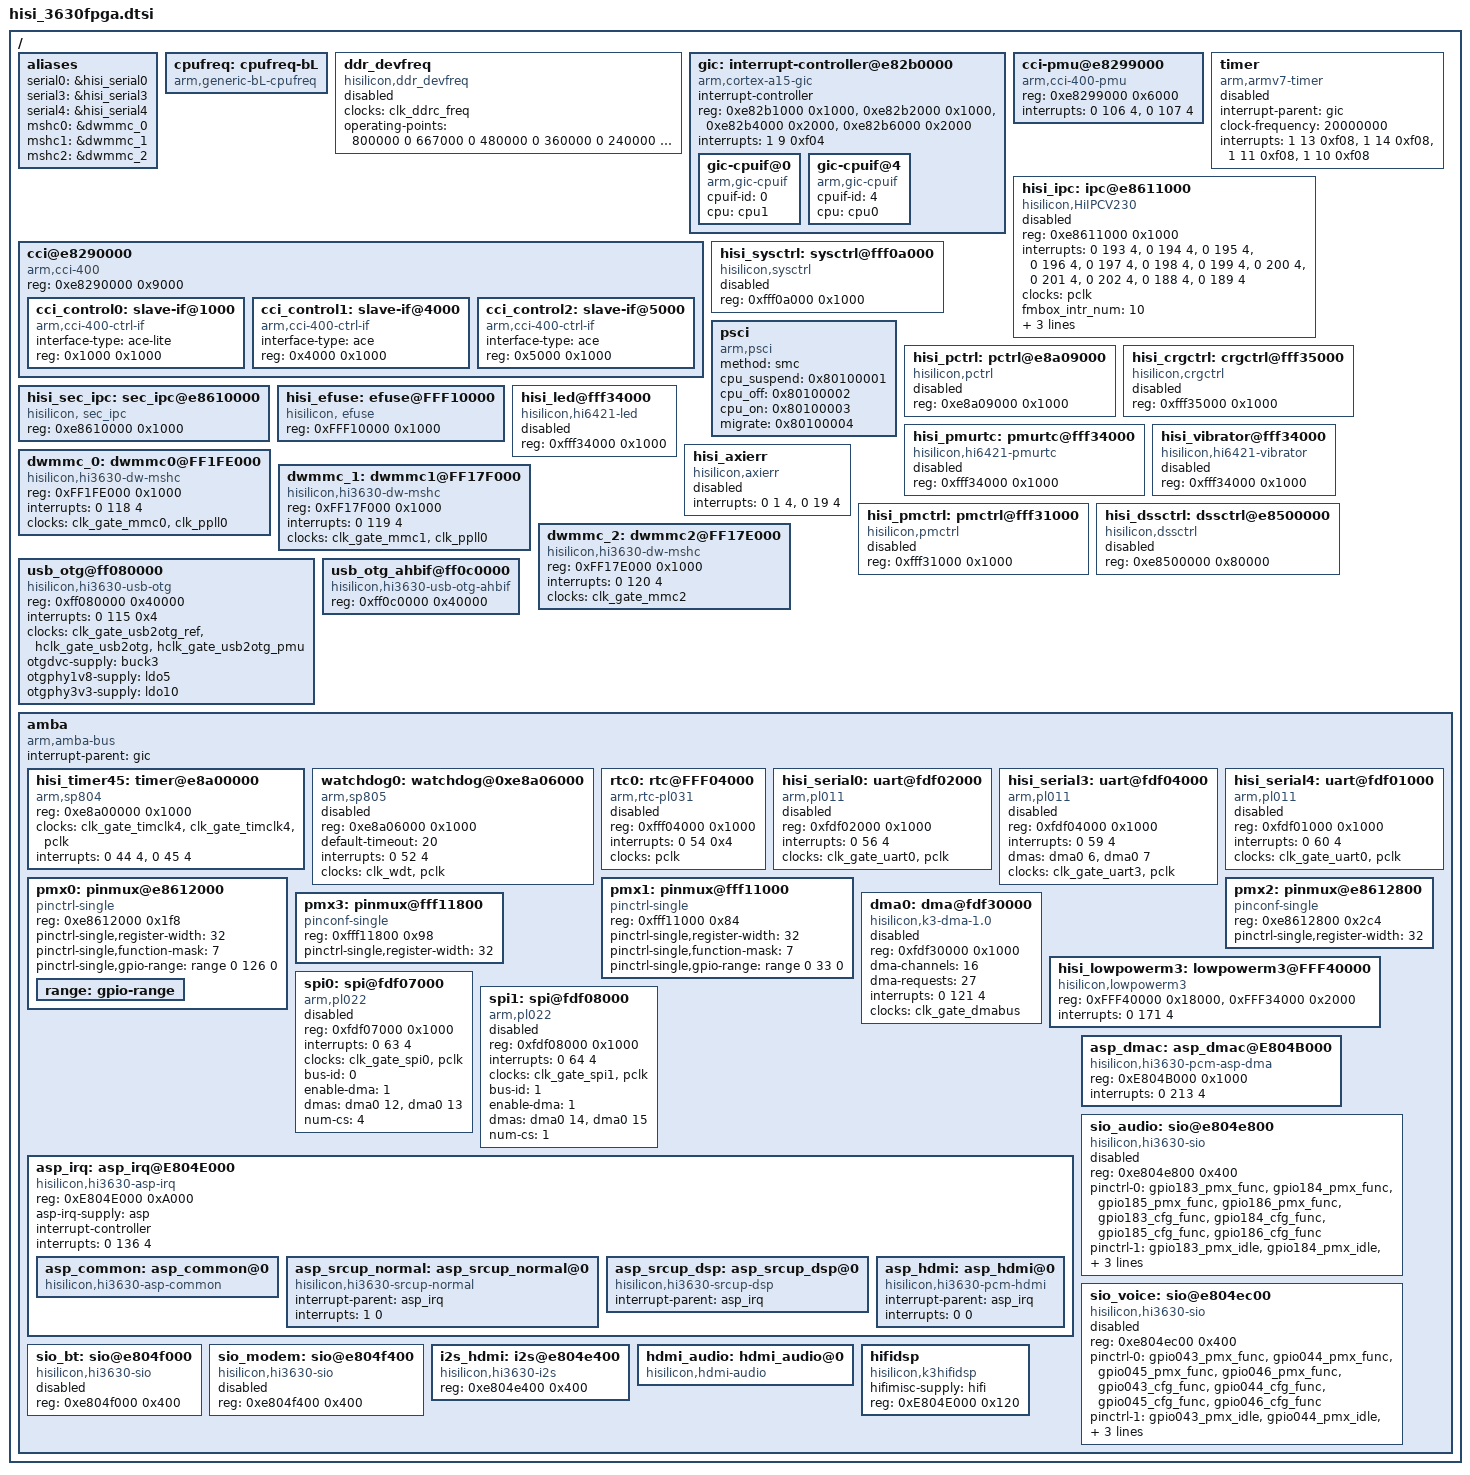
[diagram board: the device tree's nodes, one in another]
/*
 * Hisilicon Ltd. Hi3630FPGA SoC
 *
 * Copyright (C) 2013 Hisilicon Technologies CO., Ltd.
 *
 * This program is free software; you can redistribute it and/or modify
 * it under the terms of the GNU General Public License version 2 as
 * publishhed by the Free Software Foundation.
 */

/include/ "skeleton.dtsi"
/include/ "hisi_3630fpga_clock.dtsi"
/include/ "hisi_3630fpga_gpio.dtsi"
/include/ "hisi_3630fpga_i2c.dtsi"
/{
	aliases {
		serial0 = &hisi_serial0;
		serial3 = &hisi_serial3;
		serial4 = &hisi_serial4;
		mshc0 = &dwmmc_0;
		mshc1 = &dwmmc_1;
		mshc2 = &dwmmc_2;
	};

	/* cpufreq  device */
	cpufreq: cpufreq-bL {
		compatible = "arm,generic-bL-cpufreq";
	};

	ddr_devfreq {
		compatible = "hisilicon,ddr_devfreq";
		clocks = <&clk_ddrc_freq>;
		operating-points = <
			/* kHz    uV */
			800000	0
			667000	0
			480000	0
			360000	0
			240000	0
			120000	0
		>;
		status = "disabled";
	};

	gic: interrupt-controller@e82b0000 {
		compatible = "arm,cortex-a15-gic", "arm,cortex-a7-gic";
		#interrupt-cells = <3>;
		#address-cells = <0>;
		interrupt-controller;
		reg =	<0xe82b1000 0x1000>,
			<0xe82b2000 0x1000>,
			<0xe82b4000 0x2000>,
			<0xe82b6000 0x2000>;
		interrupts = <1 9 0xf04>;
		/*In our system, a15 cluster is in range cpuif0/cpuif1/cpuif2/cpuif3
		* a7 cluster is in range cpuif4/cpuif5/cpuif6/cpuif7
		*/
		gic-cpuif@0 {
			compatible = "arm,gic-cpuif";
			cpuif-id = <0>;
			cpu = <&cpu1>;
		};

		gic-cpuif@4 {
			compatible = "arm,gic-cpuif";
			cpuif-id = <4>;
			cpu = <&cpu0>;
		};
	};

        cci@e8290000 {
                compatible = "arm,cci-400";
                #address-cells = <1>;
                #size-cells = <1>;
                reg = <0xe8290000 0x9000>;
                ranges = <0x1000 0xe8291000 0x1000>,
			<0x4000 0xe8294000 0x1000>,
			<0x5000 0xe8295000 0x1000>;

                cci_control0: slave-if@1000 {
                        compatible = "arm,cci-400-ctrl-if";
                        interface-type = "ace-lite";
                        reg = <0x1000 0x1000>;
                };

                cci_control1: slave-if@4000 {
                        compatible = "arm,cci-400-ctrl-if";
                        interface-type = "ace";
                        reg = <0x4000 0x1000>;
                };

                cci_control2: slave-if@5000 {
                        compatible = "arm,cci-400-ctrl-if";
                        interface-type = "ace";
                        reg = <0x5000 0x1000>;
                };
        };

        cci-pmu@e8299000 {
                compatible = "arm,cci-400-pmu";
                reg = <0xe8299000 0x6000>;
                interrupts = <0 106 4>,
                             <0 107 4>;
        };

	timer {
		compatible = "arm,armv7-timer";
		interrupt-parent = <&gic>;
		clock-frequency = <20000000>;
		interrupts =
			<1 13 0xf08>,
			<1 14 0xf08>,
			<1 11 0xf08>,
			<1 10 0xf08>;
		status = "disabled";
	};

	hisi_ipc: ipc@e8611000 {
		compatible = "hisilicon,HiIPCV230";
		reg = <0xe8611000 0x1000>;
		interrupts = <0 193 4>, /* fast mbox */
			<0 194 4>,
			<0 195 4>,
			<0 196 4>,
			<0 197 4>,
			<0 198 4>,
			<0 199 4>,
			<0 200 4>,
			<0 201 4>,
			<0 202 4>,
			<0 188 4>, /* common mbox */
			<0 189 4>;
		clocks = <&pclk>;
		clock-names = "apb_pclk";
		fmbox_intr_num = <10>;
		cmbox_intr_num = <2>;
		unlock_key = <0x1ACCE551>;
		capability = <8>;
		status = "disabled";
	};

	hisi_sysctrl: sysctrl@fff0a000 {
		compatible = "hisilicon,sysctrl";
		reg = <0xfff0a000 0x1000>;
		status = "disabled";
	};

	psci {
		compatible      = "arm,psci";
		method          = "smc";
		cpu_suspend     = <0x80100001>;
		cpu_off         = <0x80100002>;
		cpu_on          = <0x80100003>;
		migrate         = <0x80100004>;
	};
	hisi_pctrl: pctrl@e8a09000 {
		compatible = "hisilicon,pctrl";
		reg = <0xe8a09000 0x1000>;
		status = "disabled";
	};

	hisi_crgctrl: crgctrl@fff35000 {
		compatible = "hisilicon,crgctrl";
		reg = <0xfff35000 0x1000>;
		status = "disabled";
	};

	hisi_sec_ipc: sec_ipc@e8610000 {
		compatible = "hisilicon, sec_ipc";
		reg = <0xe8610000 0x1000>;
	};

	hisi_efuse: efuse@FFF10000 {
		compatible = "hisilicon, efuse";
		reg = <0xFFF10000 0x1000>;
	};

	hisi_pmurtc: pmurtc@fff34000 {
		compatible = "hisilicon,hi6421-pmurtc";
		reg = <0xfff34000 0x1000>;
		status = "disabled";
	};

	hisi_led@fff34000 {
		compatible = "hisilicon,hi6421-led";
		reg = <0xfff34000 0x1000>;
		status = "disabled";
	};

	hisi_vibrator@fff34000 {
		compatible = "hisilicon,hi6421-vibrator";
		reg = <0xfff34000 0x1000>;
		status = "disabled";
	};

	hisi_axierr {
		compatible = "hisilicon,axierr";
		interrupts = <0 1 4>, <0 19 4>;
		status = "disabled";
	};

	/* emmc */
	dwmmc_0: dwmmc0@FF1FE000 {
		compatible = "hisilicon,hi3630-dw-mshc";
		reg = <0xFF1FE000 0x1000>;
		interrupts = <0 118 4>;
		#address-cells = <1>;
		#size-cells = <0>;
		clocks = <&clk_gate_mmc0>, <&clk_ppll0>;
		clock-names = "ciu", "biu";
	};

	/* sd */
	dwmmc_1: dwmmc1@FF17F000 {
		compatible = "hisilicon,hi3630-dw-mshc";
		reg = <0xFF17F000 0x1000>;
		interrupts = <0 119 4>;
		#address-cells = <1>;
		#size-cells = <0>;
		clocks = <&clk_gate_mmc1>, <&clk_ppll0>;
		clock-names = "ciu", "biu";
	};

	hisi_pmctrl: pmctrl@fff31000 {
		compatible = "hisilicon,pmctrl";
		reg = <0xfff31000 0x1000>;
		status = "disabled";
	};

	hisi_dssctrl: dssctrl@e8500000 {
		compatible = "hisilicon,dssctrl";
		reg = <0xe8500000 0x80000>;
		status = "disabled";
	};

	/* SDIO */
	dwmmc_2: dwmmc2@FF17E000 {
		compatible = "hisilicon,hi3630-dw-mshc";
		reg = <0xFF17E000 0x1000>;
		interrupts = <0 120 4>;
		#address-cells = <1>;
		#size-cells = <0>;
		clocks = <&clk_gate_mmc2>;
	};

	usb_otg@ff080000 {
		compatible = "hisilicon,hi3630-usb-otg";
		reg = <0xff080000 0x40000>;
		interrupts = <0 115 0x4>;
		clocks = <&clk_gate_usb2otg_ref &hclk_gate_usb2otg &hclk_gate_usb2otg_pmu>;
		otgdvc-supply = <&buck3>;
		otgphy1v8-supply = <&ldo5>;
		otgphy3v3-supply = <&ldo10>;
	};

	usb_otg_ahbif@ff0c0000 {
		compatible = "hisilicon,hi3630-usb-otg-ahbif";
		reg = <0xff0c0000 0x40000>;
	};

	amba{
		#address-cells = <1>;
		#size-cells = <1>;
		compatible = "arm,amba-bus";
		interrupt-parent = <&gic>;
		ranges;

		/*hisi_timer01: timer@fff00000 {
			compatible = "arm,sp804", "arm,primecell";
			reg = <0xfff00000 0x1000>;
			clocks = <&clk_gate_timclk0 &clk_gate_timclk0 &pclk>;
			clock-names = "clk_timclk0", "clk_timclk1","apb_pclk";
			interrupts = <0 36 4>,<0 37 4>;
			status = "disabled";
		};*/

		hisi_timer45: timer@e8a00000 {
                        compatible = "arm,sp804", "arm,primecell";
                        reg = <0xe8a00000 0x1000>;
                        clocks = <&clk_gate_timclk4 &clk_gate_timclk4 &pclk>;
                        clock-names = "clk_timclk4", "clk_timclk5","apb_pclk";
                        interrupts = <0 44 4>,<0 45 4>;
                        status = "ok";
                };

		watchdog0: watchdog@0xe8a06000 {
			compatible = "arm,sp805", "arm,primecell";
			reg = <0xe8a06000 0x1000>;
			default-timeout = <20>;
			interrupts = <0 52 4>;
			clocks = <&clk_wdt &pclk>;
			clock-names = "clk_wdt", "apb_pclk";
			status = "disabled";
		};

		rtc0: rtc@FFF04000 {
				compatible = "arm,rtc-pl031", "arm,primecell";
				reg = <0xfff04000 0x1000>;
				interrupts = <0 54 0x4>;
				clocks = <&pclk>;
				clock-names = "apb_pclk";
				status = "disabled";
		};

		hisi_serial0: uart@fdf02000 {
			compatible = "arm,pl011", "arm,primecell";
			reg = <0xfdf02000 0x1000>;
			interrupts = <0 56 4>;
			clocks = <&clk_gate_uart0 &pclk>;
			clock-names = "clk_gate_uart0", "apb_pclk";
			status = "disabled";
		};
		hisi_serial3: uart@fdf04000 {  
			compatible = "arm,pl011", "arm,primecell";  
			reg = <0xfdf04000 0x1000>;  
			interrupts = <0 59 4>;  
			dmas = <&dma0 6        /* read channel */  
			&dma0 7>;      /* write channel */  
			dma-names = "rx", "tx";  
			clocks = <&clk_gate_uart3 &pclk>;  
			clock-names = "clk_gate_uart3", "apb_pclk";  
			status = "disabled";  
		};  

	        hisi_serial4: uart@fdf01000 {
	             compatible = "arm,pl011", "arm,primecell";
	             reg = <0xfdf01000 0x1000>;
	             interrupts = <0 60 4>;
	             clocks = <&clk_gate_uart0 &pclk>;
	             clock-names = "clk_gate_uart0", "apb_pclk";
	             status = "disabled";
	         };

/*
		hisi_serial6: uart@fff32000 {
			compatible = "arm,pl011", "arm,primecell";
			reg = <0xfff32000 0x1000>;
			interrupts = <0 62 4>;
			clocks = <&clk_uart6 &pclk>;
			clock-names = "uart6clk", "apb_pclk";
			status = "disabled";
		};
*/

		pmx0: pinmux@e8612000 {
			compatible = "pinctrl-single";
			reg = <0xe8612000 0x1f8>;
			#address-cells = <1>;
			#size-cells = <1>;
			#gpio-range-cells = <3>;
			ranges;

			pinctrl-single,register-width = <32>;
			pinctrl-single,function-mask = <7>;
			/* pin base, nr pins & gpio function */
			pinctrl-single,gpio-range = <&range 0 126 0>;

			range: gpio-range {
				#pinctrl-single,gpio-range-cells = <3>;
			};
		};

		pmx1: pinmux@fff11000 {
			compatible = "pinctrl-single";
			reg = <0xfff11000 0x84>;
			#address-cells = <1>;
			#size-cells = <1>;
			#gpio-range-cells = <3>;
			ranges;

			pinctrl-single,register-width = <32>;
			pinctrl-single,function-mask = <7>;
			/* pin base, nr pins & gpio function */
			pinctrl-single,gpio-range = <&range 0 33 0>;
		};

		pmx2: pinmux@e8612800 {
			compatible = "pinconf-single";
			reg = <0xe8612800 0x2c4>;
			#address-cells = <1>;
			#size-cells = <1>;
			ranges;

			pinctrl-single,register-width = <32>;
		};

		pmx3: pinmux@fff11800 {
			compatible = "pinconf-single";
			reg = <0xfff11800 0x98>;
			#address-cells = <1>;
			#size-cells = <1>;
			ranges;

			pinctrl-single,register-width = <32>;
		};

		dma0: dma@fdf30000 {
			compatible = "hisilicon,k3-dma-1.0";
			reg = <0xfdf30000 0x1000>;
			#dma-cells = <1>;
			dma-channels = <16>;
			dma-requests = <27>;
			interrupts = <0 121 4>;
			clocks = <&clk_gate_dmabus>;
			status = "disable";
		};
		hisi_lowpowerm3: lowpowerm3@FFF40000 {
			compatible = "hisilicon,lowpowerm3";
			reg = <0xFFF40000 0x18000>, <0xFFF34000 0x2000>;
			interrupts = <0 171 4>;
		};

		spi0: spi@fdf07000 {
			compatible = "arm,pl022", "arm,primecell";
			reg = <0xfdf07000 0x1000>;
			interrupts = <0 63 4>;
			clocks = <&clk_gate_spi0 &pclk>;
			clock-names = "clk_spi0", "apb_pclk";
			bus-id = <0>;
			enable-dma = <1>;
			dmas =	<&dma0 12	   /* read channel */
				 &dma0 13>;	   /* write channel */
			dma-names = "rx", "tx";
			num-cs = <4>;
			status = "disabled";
		};

		spi1: spi@fdf08000 {
			compatible = "arm,pl022", "arm,primecell";
			reg = <0xfdf08000 0x1000>;
			interrupts = <0 64 4>;
			clocks = <&clk_gate_spi1 &pclk>;
			clock-names = "clk_spi1", "apb_pclk";
			bus-id = <1>;
			enable-dma = <1>;
			dmas =	<&dma0 14	   /* read channel */
				 &dma0 15>;	   /* write channel */
			dma-names = "rx", "tx";
			num-cs = <1>;
			status = "disabled";
		};

		asp_irq: asp_irq@E804E000 {
			compatible = "hisilicon,hi3630-asp-irq";
			reg = <0xE804E000 0xA000>;
			#interrupt-cells = <2>;
			asp-irq-supply = <&asp>;
			interrupt-controller;
			interrupts = <0 136 4>;
			interrupt-names = "asp_irq";

			asp_common: asp_common@0 {
				compatible = "hisilicon,hi3630-asp-common";
			};
			asp_srcup_normal: asp_srcup_normal@0 {
				compatible = "hisilicon,hi3630-srcup-normal";
				interrupt-parent = <&asp_irq>;
				interrupts = <1 0>;
				interrupt-names = "asp_srcup_normal";
			};
			asp_srcup_dsp: asp_srcup_dsp@0 {
				compatible = "hisilicon,hi3630-srcup-dsp";
				interrupt-parent = <&asp_irq>;
			};
			asp_hdmi: asp_hdmi@0 {
				compatible = "hisilicon,hi3630-pcm-hdmi";
				interrupt-parent = <&asp_irq>;
				interrupts = <0 0>;
				interrupt-names = "asp_irq_hdmi";
			};
		};
		asp_dmac: asp_dmac@E804B000 {
			compatible = "hisilicon,hi3630-pcm-asp-dma";
			reg = <0xE804B000 0x1000>;
			interrupts = <0 213 4>;
			interrupt-names = "asp_dma_irq";
		};
		sio_audio: sio@e804e800 {
			compatible = "hisilicon,hi3630-sio";
			reg = <0xe804e800 0x400>;
			pinctrl-names = "default", "idle";
			pinctrl-0 = <&gpio183_pmx_func
				     &gpio184_pmx_func
				     &gpio185_pmx_func
				     &gpio186_pmx_func
				     &gpio183_cfg_func
				     &gpio184_cfg_func
				     &gpio185_cfg_func
				     &gpio186_cfg_func>;
			pinctrl-1 = <&gpio183_pmx_idle
				     &gpio184_pmx_idle
				     &gpio185_pmx_idle
				     &gpio186_pmx_idle
				     &gpio183_cfg_idle
				     &gpio184_cfg_idle
				     &gpio185_cfg_idle
				     &gpio186_cfg_idle>;
			status = "disable";
		};
		sio_voice: sio@e804ec00 {
			compatible = "hisilicon,hi3630-sio";
			reg = <0xe804ec00 0x400>;
			pinctrl-names = "default", "idle";
			pinctrl-0 = <&gpio043_pmx_func
				     &gpio044_pmx_func
				     &gpio045_pmx_func
				     &gpio046_pmx_func
				     &gpio043_cfg_func
				     &gpio044_cfg_func
				     &gpio045_cfg_func
				     &gpio046_cfg_func>;
			pinctrl-1 = <&gpio043_pmx_idle
				     &gpio044_pmx_idle
				     &gpio045_pmx_idle
				     &gpio046_pmx_idle
				     &gpio043_cfg_idle
				     &gpio044_cfg_idle
				     &gpio045_cfg_idle
				     &gpio046_cfg_idle>;
			status = "disable";
		};
		sio_bt: sio@e804f000 {
			compatible = "hisilicon,hi3630-sio";
			reg = <0xe804f000 0x400>;
			/*
			pinctrl-names = "default", "idle";
			pinctrl-0 = <&gpio187_pmx_func
				     &gpio188_pmx_func
				     &gpio189_pmx_func
				     &gpio190_pmx_func
				     &gpio187_cfg_func
				     &gpio188_cfg_func
				     &gpio189_cfg_func
				     &gpio190_cfg_func>;
			pinctrl-1 = <&gpio187_pmx_idle
				     &gpio188_pmx_idle
				     &gpio189_pmx_idle
				     &gpio190_pmx_idle
				     &gpio187_cfg_idle
				     &gpio188_cfg_idle
				     &gpio189_cfg_idle
				     &gpio190_cfg_idle>;
			*/
			status = "disable";
		};
		sio_modem: sio@e804f400 {
			compatible = "hisilicon,hi3630-sio";
			reg = <0xe804f400 0x400>;
			/*
			pinctrl-names = "default", "idle";
			pinctrl-0 = <&gpio191_pmx_func
				     &gpio192_pmx_func
				     &gpio193_pmx_func
				     &gpio194_pmx_func
				     &gpio191_cfg_func
				     &gpio192_cfg_func
				     &gpio193_cfg_func
				     &gpio194_cfg_func>;
			pinctrl-1 = <&gpio191_pmx_idle
				     &gpio192_pmx_idle
				     &gpio193_pmx_idle
				     &gpio194_pmx_idle
				     &gpio191_cfg_idle
				     &gpio192_cfg_idle
				     &gpio193_cfg_idle
				     &gpio194_cfg_idle>;
			*/
			status = "disable";
		};
		i2s_hdmi: i2s@e804e400 {
			compatible = "hisilicon,hi3630-i2s";
			reg = <0xe804e400 0x400>;
		};
		hdmi_audio: hdmi_audio@0 {
			compatible = "hisilicon,hdmi-audio";
		};
		hifidsp {
			compatible = "hisilicon,k3hifidsp";
			hifimisc-supply =<&hifi>;
			reg = <0xE804E000 0x120>;
		};
	};
};
